# PIC32CX1025MTSH128S1 register map
Vendor: Microchip Technology; Series: PIC32CXMTSH; File version: 0
CPU: CM4 r0p1, selectable endian, MPU, FPU, 4 interrupt priority bits
Registers are 32-bit, read-write, reset 0x0 unless marked. A register's access mark holds for its fields unless they carry their own. Offsets are from the block's base; [hi:lo] are bit positions; {n}, {i} and the like mark numbered series; 'fields as' and 'values as' point back to an identical list.

## EMAFE — Energy Metering Analog Front End
Base 0x48000000; register names take the prefix EMAFE_
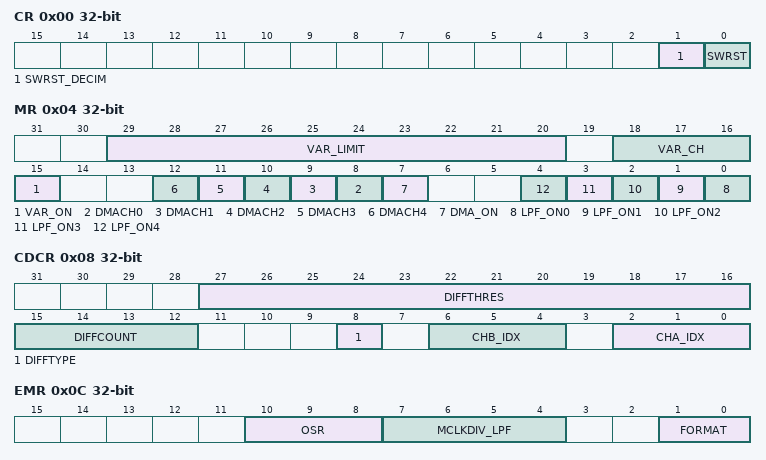
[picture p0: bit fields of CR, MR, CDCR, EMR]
0x00 CR wo — Control Register
  [1] SWRST_DECIM — Sinc Decimation Filters Reset
  [0] SWRST — Software Reset
0x04 MR — Mode Register
  [29:20] VAR_LIMIT — Variation Detection Limit for Event Triggering
  [18:16] VAR_CH — Variation Detection Channel Selection
    {v}=CH{v} (Channel {v} is selected.) (v=0..6)
  [15] VAR_ON — Variation Detection On
  [n+8] DMACH{n} (n=0..4) — Channel {n} Enable for DMA transfer
  [7] DMA_ON — Direct Memory Access On
  [n] LPF_ON{n} (n=0..4) — Low-Pass Filter {n} On
0x08 CDCR — Channels Difference Comparison Register
  [27:16] DIFFTHRES — Threshold
  [15:12] DIFFCOUNT — Successive Comparison Event Count
  [8] DIFFTYPE — Type of Comparison
  [6:4] CHB_IDX — Second Channel to Compare
    {v}=CH{v} (Channel {v} is used to perform comparison) (v=0..4); 5=CH5 (Channel 5 is used to perform comparison.); 6=CH6 (Channel 6 is used to perform comparison.)
  [2:0] CHA_IDX — First Channel to Compare
    {v}=CH{v} (Channel {v} is used to perform comparison.) (v=0..6)
0x0C EMR — Extended Mode Register
  [10:8] OSR — OSR of the Decimation Filters
    0=OSR of the system is 8; 1=OSR of the system is 16; 2=OSR of the system is 32; 3=OSR of the system is 64 (Default)
  [7:4] MCLKDIV_LPF — LPF Clock Prescaler Ratio
    0=MCLK (LPFIF clock is MCLK/1.); 1=MCLKDIV2 (LPFIF clock is MCLK/2.); 2=MCLKDIV4 (LPFIF clock is MCLK/4.); 3=MCLKDIV8 (LPFIF clock is MCLK/8. (Default)); 4=MCLKDIV16 (LPFIF clock is MCLK/16.); 5=MCLKDIV32 (LPFIF clock is MCLK/32.)
  [1:0] FORMAT — Data Format
    0=NB_CHANNEL (Index of channel is added in register EMAFE_DMA_DATA. 24-bit dynamic range. (default).); 1=SIGNEXTEND (24-bit value with sign extension up to 32-bit applied to registers EMAFE_DMA_DATA and EMAFE _DATAx. 24-bit dynamic range); 2=FULLRANGE (32-bit full range signed extension is applied in EMAFE_DMA_DATA and EMAFE _DATAx. 32-bit dynamic range.)
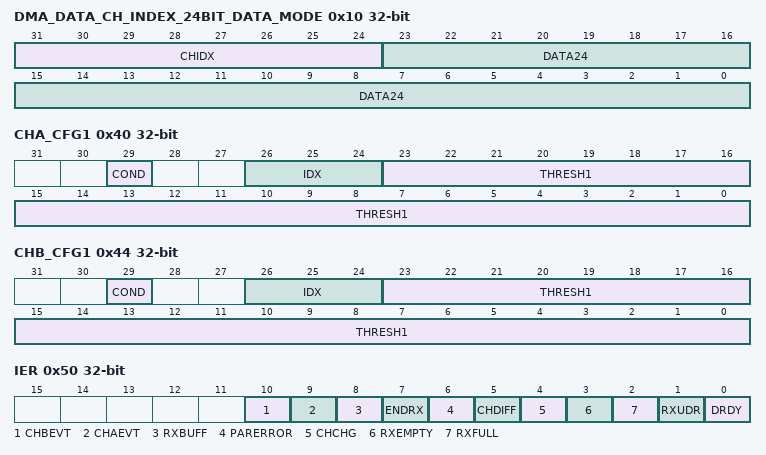
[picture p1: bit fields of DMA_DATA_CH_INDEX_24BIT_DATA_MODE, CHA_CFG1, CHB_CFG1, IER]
0x10 DMA_DATA_CH_INDEX_24BIT_DATA_MODE ro — DMA Data Register
  [31:24] CHIDX — Channel Index
  [23:0] DATA24 — 24-bit Data read by DMA
0x10 DMA_DATA_ONLY_32BIT_DATA_SE24BIT_MODE ro (alternate view of DMA_DATA_CH_INDEX_24BIT_DATA_MODE) — DMA Data Register
  [31:0] DATA24SE — Low-pass Filter 24-bit Data with 32-bit Sign Extension read by DMA
0x10 DMA_DATA_ONLY_32BIT_DATA_MODE ro (alternate view of DMA_DATA_CH_INDEX_24BIT_DATA_MODE) — DMA Data Register
  [31:0] DATA32 — 32-bit Data read by DMA
{0x14+4i} DATA_DATA_24BIT_MODE[{i}] (i=0..4) ro — Data Channel 0 Register
  [23:0] DATA24 — Low-pass Filter 24-bit Signed Data
{0x14+4i} DATA_SE_24BIT_DATA_MODE[{i}] (i=0..4) ro (alternate view of DATA_DATA_24BIT_MODE[{i}]) — Data Channel 0 Register
  [31:0] DATA24SE — Low-pass Filter 24-bit Data with 32-bit Sign Extension
{0x14+4i} DATA_DATA_32BIT_MODE[{i}] (i=0..4) ro (alternate view of DATA_DATA_24BIT_MODE[{i}]) — Data Channel 0 Register
  [31:0] DATA32 — Low-pass Filter 32-bit Signed Data
0x40 CHA_CFG1 — Channel A Comparison Configuration 1
  [29] COND — Condition Applied for Detection on Channel A
    0=OR (Selected channel data is lower than THRESH1 OR higher than THRESH2.); 1=AND (Selected channel data is lower than THRESH1 AND higher than THRESH2.)
  [26:24] IDX — Channel A Index
    {v}=CH{v} (Channel {v} is selected.) (v=0..6)
  [23:0] THRESH1 — Threshold 1 for Channel A
0x44 CHB_CFG1 — Channel B Comparison Configuration 1
  [29] COND — Condition Applied for Detection on Channel B
    values as CHA_CFG1.COND
  [26:24] IDX — Channel B Index
    {v}=CH{v} (Channel {v} is selected.) (v=0..6)
  [23:0] THRESH1 — Threshold 1 for Channel B
0x48 CHA_CFG2 — Channel A Comparison Configuration 2
  [23:0] THRESH2 — Threshold 2 for Channel A
0x4C CHB_CFG2 — Channel B Comparison Configuration 2
  [23:0] THRESH2 — Threshold 2 for Channel B
0x50 IER wo — Interrupt Enable Register
  [10] CHBEVT — Channel B Event Interrupt Enable
  [9] CHAEVT — Channel A Event Interrupt Enable
  [8] RXBUFF — PDC Receive Buffer Full Interrupt Enable
  [7] ENDRX — PDC Receive Transfer End Interrupt Enable
  [6] PARERROR — Parity Error Interrupt Enable
  [5] CHDIFF — Comparison Flag Interrupt Enable
  [4] CHCHG — Channel Data Change Interrupt Enable
  [3] RXEMPTY — Receive FIFO Empty Interrupt Enable
  [2] RXFULL — Receive FIFO Full Interrupt Enable
  [1] RXUDR — Receive Underflow Flow Interrupt Enable
  [0] DRDY — Data Ready Interrupt Enable
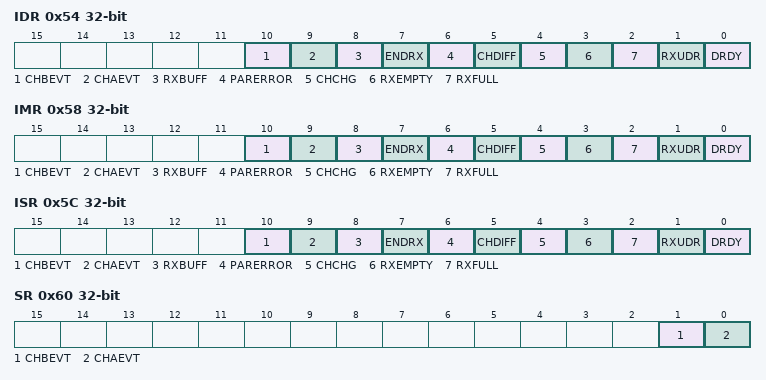
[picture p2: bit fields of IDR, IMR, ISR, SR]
0x54 IDR wo — Interrupt Disable Register
  [10] CHBEVT — Threshold Channel B Interrupt Disable
  [9] CHAEVT — Threshold Channel A Interrupt Disable
  [8] RXBUFF — PDC Receive Buffer Full Interrupt Disable
  [7] ENDRX — PDC Receive Transfer End Interrupt Disable
  [6] PARERROR — Parity Error Interrupt Disable
  [5] CHDIFF — Comparison Flag Interrupt Disable
  [4] CHCHG — Channel Data Change Interrupt Disable
  [3] RXEMPTY — Receive FIFO Empty Interrupt Disable
  [2] RXFULL — Receive FIFO Full Interrupt Disable
  [1] RXUDR — Receive Underflow Flow Interrupt Disable
  [0] DRDY — Data Ready Interrupt Disable
0x58 IMR ro — Interrupt Mask Register
  [10] CHBEVT — Channel B Interrupt Mask
  [9] CHAEVT — Channel A Interrupt Mask
  [8] RXBUFF — PDC Receive Buffer Full Interrupt Mask
  [7] ENDRX — PDC Receive Transfer End Interrupt Mask
  [6] PARERROR — Parity Error Interrupt Mask
  [5] CHDIFF — Comparison Flag Interrupt Mask
  [4] CHCHG — Channel Data Change Interrupt Mask
  [3] RXEMPTY — Receive FIFO Empty Interrupt Mask
  [2] RXFULL — Receive FIFO Full Interrupt Mask
  [1] RXUDR — Receive Underflow Flow Interrupt Mask
  [0] DRDY — Data Ready Interrupt Mask
0x5C ISR ro — Interrupt Status Register
  [10] CHBEVT — Channel B Event (cleared on read)
  [9] CHAEVT — Channel A Event (cleared on read)
  [8] RXBUFF — PDC Receive Buffer Full Event (cleared by writing EMAFE_RCR or EMAFE_RNCR)
  [7] ENDRX — PDC Receive Transfer End Event (cleared by writing EMAFE_RCR or EMAFE_RNCR)
  [6] PARERROR — Parity Error Event (cleared on read)
  [5] CHDIFF — Channel Difference Comparison Event (cleared on read)
  [4] CHCHG — Channel Data Variation Detection Event (cleared on read)
  [3] RXEMPTY — Receive FIFO Empty (cleared on read)
  [2] RXFULL — Receive FIFO Full (cleared on read)
  [1] RXUDR — Receive Under Flow (cleared on read)
  [0] DRDY — Data Ready (cleared on read)
0x60 SR ro — Status Register
  [1] CHBEVT — Event on Channel B
  [0] CHAEVT — Event on Channel A
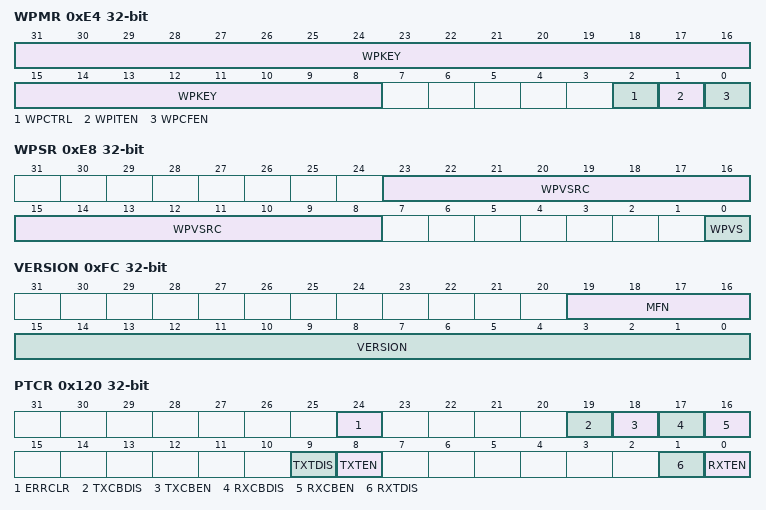
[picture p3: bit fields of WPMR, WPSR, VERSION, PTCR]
0xE4 WPMR — Write Protection Mode Register
  [31:8] WPKEY — Write Protection Key
    0x768070=PASSWD (Writing any other value in this field aborts the write operation of the WPCFEN and WPITEN bit. Always reads as 0.)
  [2] WPCTRL — Write Protection Control
  [1] WPITEN — Write Protection Interrupt Enable
  [0] WPCFEN — Write Protection Configuration Enable
0xE8 WPSR ro — Write Protection Status Register
  [23:8] WPVSRC — Write Protection Violation Source
  [0] WPVS — Write Protection Violation Status
0xFC VERSION ro
  [19:16] MFN — Metal Fix Number
  [15:0] VERSION — Version of the Hardware Module
0x100 RPR — Receive Pointer Register
  [31:0] RXPTR
0x104 RCR — Receive Counter Register
  [15:0] RXCTR
0x110 RNPR — Receive Next Pointer Register
  [31:0] RXNPTR — Receive Next Pointer
0x114 RNCR — Receive Next Counter Register
  [15:0] RXNCTR — Receive Next Counter
0x120 PTCR wo — Transfer Control Register
  [24] ERRCLR — Transfer Bus Error Clear
  [19] TXCBDIS — Transmitter Circular Buffer Disable
  [18] TXCBEN — Transmitter Circular Buffer Enable
  [17] RXCBDIS — Receiver Circular Buffer Disable
  [16] RXCBEN — Receiver Circular Buffer Enable
  [9] TXTDIS — Transmitter Transfer Disable
  [8] TXTEN — Transmitter Transfer Enable
  [1] RXTDIS — Receiver Transfer Disable
  [0] RXTEN — Receiver Transfer Enable
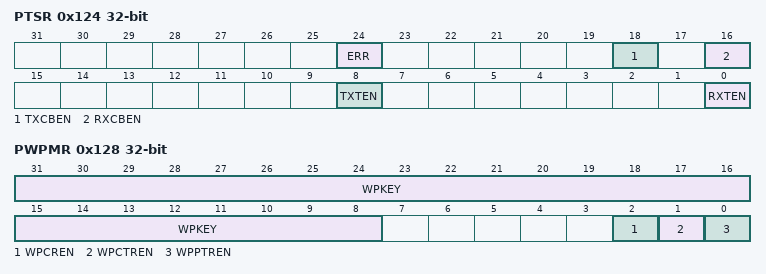
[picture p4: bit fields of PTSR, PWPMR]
0x124 PTSR ro — Transfer Status Register
  [24] ERR — Transfer Bus Error
  [18] TXCBEN — Transmitter Circular Buffer Enable
  [16] RXCBEN — Receiver Circular Buffer Enable
  [8] TXTEN — Transmitter Transfer Enable
  [0] RXTEN — Receiver Transfer Enable
0x128 PWPMR — Write Protection Mode Register
  [31:8] WPKEY — Write Protection Key
    0x504443=PASSWD (Writing any other value in this field aborts the write operation. Always reads as 0.)
  [2] WPCREN — Write Protection Control Register Enable
  [1] WPCTREN — Write Protection Counter Registers Enable
  [0] WPPTREN — Write Protection Pointer Registers Enable
